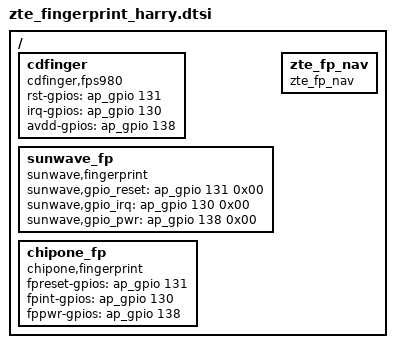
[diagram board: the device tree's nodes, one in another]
/ {
	cdfinger {
		compatible = "cdfinger,fps980";
		rst-gpios = <&ap_gpio 131 0x00>;
		irq-gpios = <&ap_gpio 130 0x00>;
		avdd-gpios = <&ap_gpio 138 0x00>;
	};
	sunwave_fp {
		compatible = "sunwave,fingerprint";
		sunwave,gpio_reset = <&ap_gpio 131 0x00>;
		sunwave,gpio_irq = <&ap_gpio 130 0x00>;
		sunwave,gpio_pwr = <&ap_gpio 138 0x00>;
	};
	chipone_fp {
		compatible = "chipone,fingerprint";
		fpreset-gpios = <&ap_gpio 131 0x00>;
		fpint-gpios = <&ap_gpio 130 0x00>;
		fppwr-gpios = <&ap_gpio 138 0x00>;
	};
	/*fingerprint nav*/
	zte_fp_nav: zte_fp_nav {
		status="okay";
		compatible = "zte_fp_nav";
	};
};
